# PIC32MZ2064DAG176 device description
Architecture: MIPS; Family: PIC32MZDA; Series: PIC32MZ
Registers are 32-bit, read-write, no defined reset value unless marked. A register's access mark holds for its fields unless they carry their own. Offsets are from the block's base; [hi:lo] are bit positions; {n}, {i} and the like mark numbered series; 'fields as' and 'values as' point back to an identical list.

## CFG
Instances: CFG 0x1f800000 in periph_pb1_std
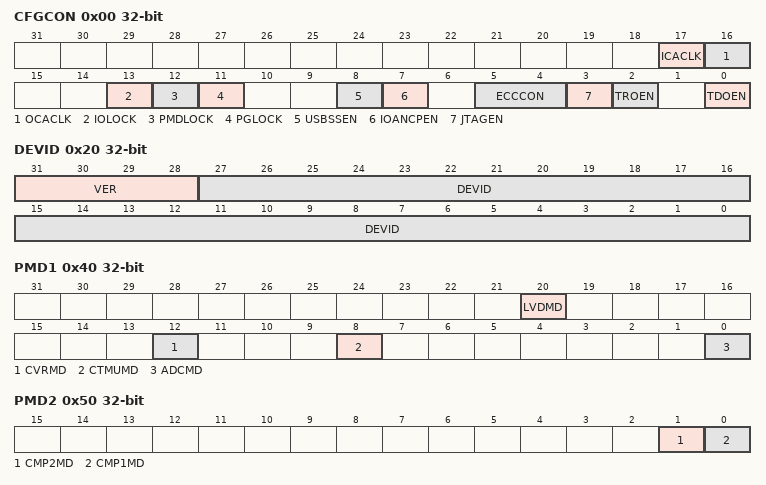
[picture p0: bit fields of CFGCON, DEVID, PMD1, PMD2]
0x00 CFGCON — Configuration Control Register
  [17] ICACLK — Input Capture Alternate Clock Selection bit(1)
    1=Input Capture modules use an alternative Timer pair as their timebase clock; 0=All Input Capture modules use Timer2/3 as their timebase clock
  [16] OCACLK — Output Compare Alternate Clock Selection bit(1)
    1=Output Compare modules use an alternative Timer pair as their timebase clock; 0=All Output Compare modules use Timer2/3 as their timebase clock
  [13] IOLOCK — Peripheral Pin Select Lock bit(1)
    1=Peripheral Pin Select is locked. Writes to PPS registers is not allowed.; 0=Peripheral Pin Select is not locked. Writes to PPS registers is allowed.
  [12] PMDLOCK — Peripheral Module Disable bit(1)
    1=Peripheral module is locked. Writes to PMD registers is not allowed.; 0=Peripheral module is not locked. Writes to PMD registers is allowed.
  [11] PGLOCK — Permission Group Lock bit(1)
    1=Permission Group registers are locked. Writes to PG registers are not allowed.; 0=Permission Group registers are not locked. Writes to PG registers are allowed.
  [8] USBSSEN — USB Suspend Sleep Enable bit(1)
    1=USB PHY clock is shut down when Sleep mode is active; 0=USB PHY clock continues to run when Sleep is active
  [7] IOANCPEN — I/O Analog Charge Pump Enable bit
    1=Charge pumps are enabled; 0=Charge pumps are disabled
  [5:4] ECCCON — Flash ECC Configuration bits
    3=ECC and dynamic ECC are disabled (ECCCON bits are writable); 2=ECC and dynamic ECC are disabled (ECCCON bits are locked); 1=Dynamic Flash ECC is enabled (ECCCON bits are locked); 0=Flash ECC is enabled (ECCCON bits are locked; disables word Flash writes)
  [3] JTAGEN — JTAG Port Enable bit
    1=Enable the JTAG port; 0=Disable the JTAG port
  [2] TROEN — Trace Output Enable bit
    1=Enable trace outputs and start trace clock (trace probe must be present); 0=Disable trace outputs and stop trace clock
  [0] TDOEN — TDO Enable for 2-Wire JTAG
    1=2-wire JTAG protocol uses TDO; 0=2-wire JTAG protocol does not use TDO
0x20 DEVID — Device and Revision ID Register
  [31:28] VER, [27:0] DEVID
0x30 SYSKEY
0x40 PMD1
  [20] LVDMD, [12] CVRMD, [8] CTMUMD, [0] ADCMD
0x50 PMD2
  [1] CMP2MD, [0] CMP1MD
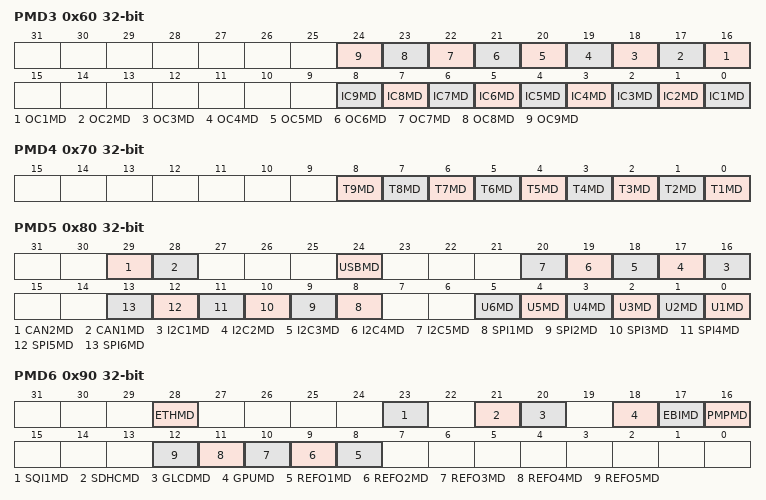
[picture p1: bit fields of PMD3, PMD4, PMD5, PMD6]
0x60 PMD3
  [n+15] OC{n}MD (n=1..9), [n-1] IC{n}MD (n=1..9)
0x70 PMD4
  [n-1] T{n}MD (n=1..9)
0x80 PMD5
  [29] CAN2MD, [28] CAN1MD, [24] USBMD, [n+15] I2C{n}MD (n=1..5), [n+7] SPI{n}MD (n=1..6), [n-1] U{n}MD (n=1..6)
0x90 PMD6
  [28] ETHMD, [23] SQI1MD, [21] SDHCMD, [20] GLCDMD, [18] GPUMD, [17] EBIMD, [16] PMPMD, [n+7] REFO{n}MD (n=1..5)
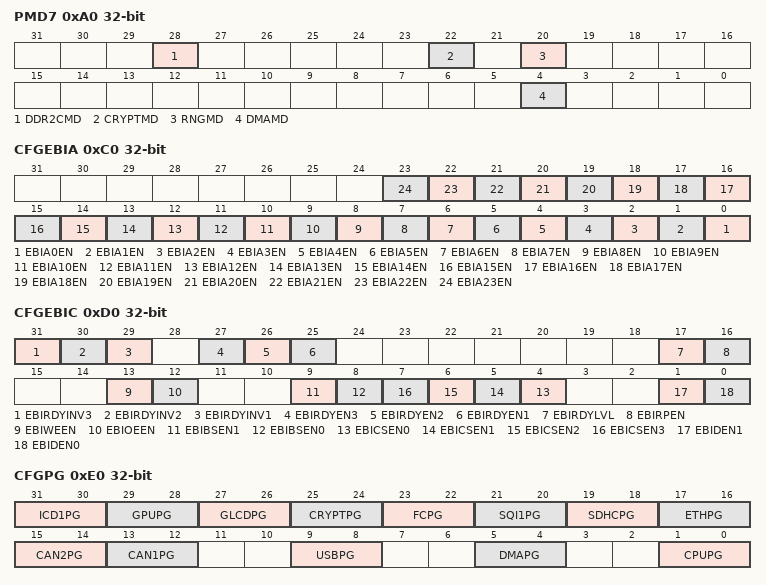
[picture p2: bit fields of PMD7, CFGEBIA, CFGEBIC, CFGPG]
0xA0 PMD7
  [28] DDR2CMD, [22] CRYPTMD, [20] RNGMD, [4] DMAMD
0xC0 CFGEBIA — External Bus Interface Address Pin Configuration Register
  [all] fields
    1=EBIAx pin is enabled for use by EBI; 0=EBIAx pin has is available for general use
  [n] EBIA{n}EN (n=0..23) — EBI Address Pin Enable bit {n}
0xD0 CFGEBIC — External Bus Interface Control Pin Configuration Register
  [31] EBIRDYINV3 — EBIRDY3 Inversion Control bit
    1=Invert EBIRDY3 pin before use; 0=Do not invert EBIRDY3 pin before use
  [30] EBIRDYINV2 — EBIRDY2 Inversion Control bit
    1=Invert EBIRDY2 pin before use; 0=Do not invert EBIRDY2 pin before use
  [29] EBIRDYINV1 — EBIRDY1 Inversion Control bit
    1=Invert EBIRDY1 pin before use; 0=Do not invert EBIRDY1 pin before use
  [27] EBIRDYEN3 — EBIRDY3 Pin Enable bit
    1=EBIRDY3 pin is enabled for use by the EBI module; 0=EBIRDY3 pin is available for general use
  [26] EBIRDYEN2 — EBIRDY2 Pin Enable bit
    1=EBIRDY2 pin is enabled for use by the EBI module; 0=EBIRDY2 pin is available for general use
  [25] EBIRDYEN1 — EBIRDY1 Pin Enable bit
    1=EBIRDY1 pin is enabled for use by the EBI module; 0=EBIRDY1 pin is available for general use
  [17] EBIRDYLVL — EBIRDYx Pin Sensitivity Control bit
    1=Use level detect for EBIRDYx pins; 0=Use edge detect for EBIRDYx pins
  [16] EBIRPEN — EBIRP Pin Sensitivity Control bit
    1=EBIRP pin is enabled for use by the EBI module; 0=EBIRP pin is available for general use
  [13] EBIWEEN — EBIWE Pin Enable bit
    1=EBIWE pin is enabled for use by the EBI module; 0=EBIWE pin is available for general use
  [12] EBIOEEN — EBIOE Pin Enable bit
    1=EBIOE pin is enabled for use by the EBI module; 0=EBIOE pin is available for general use
  [9] EBIBSEN1 — EBIBS1 Pin Enable bit
    1=EBIBS1 pin is enabled for use by the EBI module; 0=EBIBS1 pin is available for general use
  [8] EBIBSEN0 — EBIBS0 Pin Enable bit
    1=EBIBS0 pin is enabled for use by the EBI module; 0=EBIBS0 pin is available for general use
  [n+4] EBICSEN{n} (n=0..3) — EBICS{n} Pin Enable bit
    1=EBICS{n} pin is enabled for use by the EBI module; 0=EBICS{n} pin is available for general use
  [1] EBIDEN1 — EBI Data Upper Byte Pin Enable bit
    1=EBID pins are enabled for use by the EBI module; 0=EBID pins have reverted to general use
  [0] EBIDEN0 — EBI Data Upper Byte Pin Enable bit
    values as EBIDEN1
0xE0 CFGPG — Permission Group Configuration Register
  [31:30] ICD1PG
  [29:28] GPUPG — 2D Graphics Processing Unit Permission Group bits
    {v}=Initiator is assigned to Permission Group {v} (v=0..3)
  [27:26] GLCDPG — Graphics LCD Controller Permission Group bits
    {v}=Initiator is assigned to Permission Group {v} (v=0..3)
  [25:24] CRYPTPG — Crypto Engine Permission Group bits
    {v}=Initiator is assigned to Permission Group {v} (v=0..3)
  [23:22] FCPG — Flash Control Permission Group bits
    {v}=Initiator is assigned to Permission Group {v} (v=0..3)
  [21:20] SQI1PG — SQI Module Permission Group bits
    {v}=Initiator is assigned to Permission Group {v} (v=0..3)
  [19:18] SDHCPG — Secure Digital Host Controller Permission Group bits
    {v}=Initiator is assigned to Permission Group {v} (v=0..3)
  [17:16] ETHPG — Ethernet Module Permission Group bits
    {v}=Initiator is assigned to Permission Group {v} (v=0..3)
  [15:14] CAN2PG — CAN2 Module Permission Group bits
    {v}=Initiator is assigned to Permission Group {v} (v=0..3)
  [13:12] CAN1PG — CAN1 Module Permission Group bits
    {v}=Initiator is assigned to Permission Group {v} (v=0..3)
  [9:8] USBPG — USB Module Permission Group bits
    {v}=Initiator is assigned to Permission Group {v} (v=0..3)
  [5:4] DMAPG — DMA Module Permission Group bits
    {v}=Initiator is assigned to Permission Group {v} (v=0..3)
  [1:0] CPUPG — CPU Permission Group bits
    {v}=Initiator is assigned to Permission Group {v} (v=0..3)
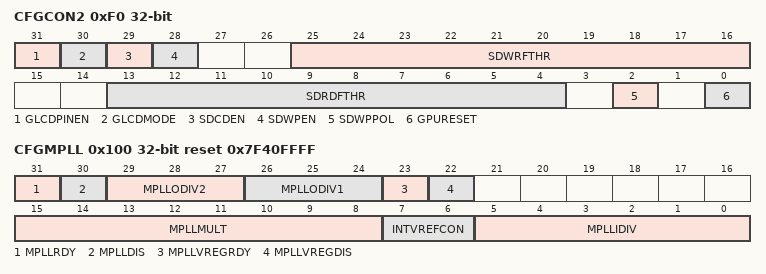
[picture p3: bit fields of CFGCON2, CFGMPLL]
0xF0 CFGCON2 — Configuration Control Register 2
  [31] GLCDPINEN — Graphics Display Pin Enable bit
    1=GLCD pins are used by the GLCD module; 0=GLCD pins are available for general purpose use
  [30] GLCDMODE — Graphics Display Mode bit
    1=GLCD pins are set to RGB565 mode. Other GDx pins are available for general purpose use.; 0=GLCD pins are set to RGB888 mode
  [29] SDCDEN — SD Card Detect Pin Enable bit
    1=SDCD pin is enabled for use by SDHC; 0=SDCD pin is available for general purpose use
  [28] SDWPEN — SD card Write Protect Enable bit
    1=SDWP pin is enabled for use by SDHC; 0=SDWP pin is available for general purpose use
  [25:16] SDWRFTHR — SDHC Write FIFO Threshold bits
  [13:4] SDRDFTHR — SDHC Read FIFO Threshold bits
  [2] SDWPPOL
    1=SDWP pin is Active-High; 0=SDWP pin is Active-Low
  [0] GPURESET — GPU Reset Bit
    1=Hold GPU in RESET; 0=Release RESET to the GPU module
0x100 CFGMPLL reset 0x7F40FFFF — Memory PLL Configuration Register
  [31] MPLLRDY — Memory PLL Status bit
    1=MPLL clock is stable and is ready for use; 0=MPLL clock is not ready. Initializing DDR2 SDRAM when the clock is not ready will result in undefined behavior.
  [30] MPLLDIS — MPLL Disable bit
    1=DISABLED (MPLL is disabled); 0=ENABLED (MPLL is enabled)
  [29:27] MPLLODIV2 — MPLL Output Divider 2 bits
    {v}=DIV_{v} (MPLL second stage output is divided by {v}) (v=1..7)
  [26:24] MPLLODIV1 — MPLL Output Divider 1 bits
    values as MPLLODIV2
  [23] MPLLVREGRDY — MPLL Voltage Regulator Ready bit
    1=MPLL voltage regulator is ready for use; 0=MPLL voltage regulator is not ready or is disabled
  [22] MPLLVREGDIS — MPLL Voltage regulator Disable bit
    1=DISABLED (MPLL voltage regulator is disabled); 0=ENABLED (MPLL voltage regulator is enabled)
  [15:8] MPLLMULT — MPLL Multiplier bits
    {v}=MUL_{v} (Multiply by {v}) (v=16..160)
  [7:6] INTVREFCON — Internal DDRV
    3=INTERNAL_DDRV (Enable the internal DDRV); 2=INTERNAL_DIS_VSS1V8 (Disable the internal DDRV and drive the DDRVREF pin to VSS1V8); 1=INTERNAL_DIS_VDDR1V8 (Disable the internal DDRV and drive the DDRVREF pin to VDDR1V8); 0=EXTERNAL_DDRV (Use the external DDRV)
  [5:0] MPLLIDIV — MPLL Input Divider bits
    {v}=DIV_{v} (MPLL input clock is divider by {v}) (v=1..63)
Value list DEVID__VER: 0x10000000=Revision A1; 0x20000000=Revision B0; 0x30000000=Revision B1

## Notices in the file
Copyright (c) 2017 Microchip Technology Inc.
SPDX-License-Identifier: Apache-2.0
Licensed under the Apache License, Version 2.0 (the "License");
you may not use this file except in compliance with the License.
You may obtain a copy of the License at
http://www.apache.org/licenses/LICENSE-2.0
Unless required by applicable law or agreed to in writing, software
distributed under the License is distributed on an "AS IS" BASIS,
WITHOUT WARRANTIES OR CONDITIONS OF ANY KIND, either express or implied.
See the License for the specific language governing permissions and
limitations under the License.
